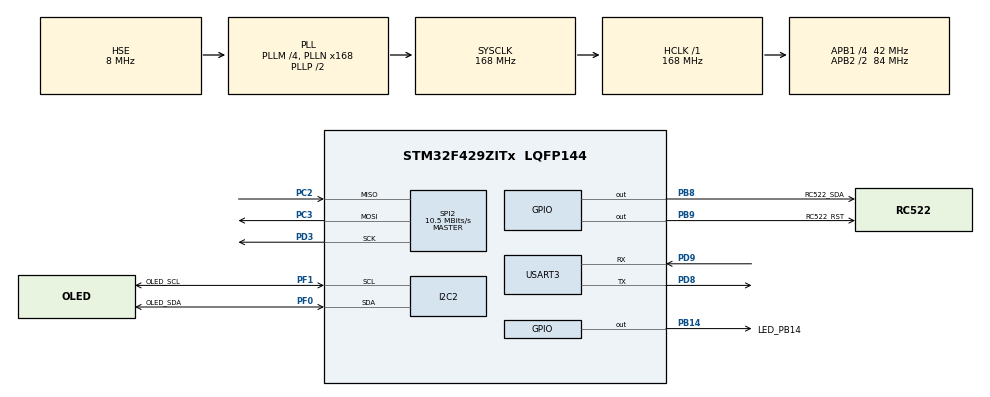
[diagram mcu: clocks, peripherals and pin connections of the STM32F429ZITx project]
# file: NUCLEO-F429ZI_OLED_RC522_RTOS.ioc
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FREERTOS.Tasks01=defaultTask,24,128,StartDefaultTask,Default,NULL,Dynamic,NULL,NULL
I2C2.I2C_Mode=I2C_Fast
Mcu.Family=STM32F4
Mcu.Name=STM32F429ZITx
Mcu.Package=LQFP144
NVIC.PriorityGroup=NVIC_PRIORITYGROUP_4
PA13.Mode=Serial_Wire
PA13.Signal=SYS_JTMS-SWDIO
PA14.Mode=Serial_Wire
PA14.Signal=SYS_JTCK-SWCLK
PB14.GPIO_Label=LED_PB14
PB14.Signal=GPIO_Output
PB8.GPIO_Label=RC522_SDA
PB8.GPIO_Speed=GPIO_SPEED_FREQ_HIGH
PB8.Signal=GPIO_Output
PB9.GPIO_Label=RC522_RST
PB9.GPIO_Speed=GPIO_SPEED_FREQ_HIGH
PB9.Signal=GPIO_Output
PC2.Mode=Full_Duplex_Master
PC2.Signal=SPI2_MISO
PC3.Mode=Full_Duplex_Master
PC3.Signal=SPI2_MOSI
PD3.Mode=Full_Duplex_Master
PD3.Signal=SPI2_SCK
PD8.Mode=Asynchronous
PD8.Signal=USART3_TX
PD9.Mode=Asynchronous
PD9.Signal=USART3_RX
PF0.GPIO_Label=OLED_SDA
PF0.Mode=I2C
PF0.Signal=I2C2_SDA
PF1.GPIO_Label=OLED_SCL
PF1.Mode=I2C
PF1.Signal=I2C2_SCL
PH0/OSC_IN.Mode=HSE-External-Oscillator
PH0/OSC_IN.Signal=RCC_OSC_IN
PH1/OSC_OUT.Mode=HSE-External-Oscillator
PH1/OSC_OUT.Signal=RCC_OSC_OUT
ProjectManager.HeapSize=0x200
ProjectManager.StackSize=0x400
ProjectManager.TargetToolchain=MDK-ARM V5.32
RCC.48MHZClocksFreq_Value=48000000
RCC.AHBFreq_Value=168000000
RCC.APB1CLKDivider=RCC_HCLK_DIV4
RCC.APB1Freq_Value=42000000
RCC.APB1TimFreq_Value=84000000
RCC.APB2CLKDivider=RCC_HCLK_DIV2
RCC.APB2Freq_Value=84000000
RCC.APB2TimCLKDivider=2
RCC.APB2TimFreq_Value=168000000
RCC.CortexFreq_Value=168000000
RCC.HCLKFreq_Value=168000000
RCC.HSE_VALUE=8000000
RCC.HSI_VALUE=16000000
RCC.LSE_VALUE=32768
RCC.PLLM=4
RCC.PLLMUL=RCC_PLL_MUL9
RCC.PLLN=168
RCC.PLLQ=7
RCC.PLLSourceVirtual=RCC_PLLSOURCE_HSE
RCC.PRESCALERUSB=RCC_USBCLKSOURCE_PLL_DIV1_5
RCC.SYSCLKFreq_VALUE=168000000
RCC.SYSCLKSource=RCC_SYSCLKSOURCE_PLLCLK
RCC.SYSCLKSourceVirtual=RCC_SYSCLKSOURCE_PLLCLK
RCC.USBFreq_Value=48000000
RCC.VCOOutputFreq_Value=336000000
SPI2.BaudRatePrescaler=SPI_BAUDRATEPRESCALER_4
SPI2.CalculateBaudRate=10.5 MBits/s
SPI2.Direction=SPI_DIRECTION_2LINES
SPI2.Mode=SPI_MODE_MASTER
SPI2.VirtualType=VM_MASTER
USART3.VirtualMode=VM_ASYNC
VP_FREERTOS_VS_CMSIS_V2.Mode=CMSIS_V2
board=NUCLEO-F429ZI

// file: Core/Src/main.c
/* USER CODE BEGIN Header */
/**
  ******************************************************************************
  * @file           : main.c
  * @brief          : Main program body
  ******************************************************************************
  * @attention
  *
  * Copyright (c) 2025 STMicroelectronics.
  * All rights reserved.
  *
  * This software is licensed under terms that can be found in the LICENSE file
  * in the root directory of this software component.
  * If no LICENSE file comes with this software, it is provided AS-IS.
  *
  ******************************************************************************
  */
/* USER CODE END Header */
#include "main.h"
#include "cmsis_os.h"
#include "i2c.h"
#include "spi.h"
#include "usart.h"
#include "gpio.h"

/* USER CODE BEGIN Includes */
#include "rc522.h"
#include "oled_driver.h"
#include "oled_rtos_task.h"
#include "rc522_rtos_task.h"
/* USER CODE END Includes */

void SystemClock_Config(void);
void MX_FREERTOS_Init(void);

int main(void)
{

  /* MCU Configuration--------------------------------------------------------*/

  /* Reset of all peripherals, Initializes the Flash interface and the Systick. */
  HAL_Init();

  /* Configure the system clock */
  SystemClock_Config();

  /* Initialize all configured peripherals */
  MX_GPIO_Init();
  MX_SPI2_Init();
  MX_USART3_UART_Init();
  MX_I2C2_Init();

  /* Init scheduler */
  osKernelInitialize();

  /* Call init function for freertos objects (in cmsis_os2.c) */
  //MX_FREERTOS_Init();
  OLED_Task_Init();
  RC522_Task_Init();

  /* Start scheduler */
  osKernelStart();

  /* We should never get here as control is now taken by the scheduler */

  /* Infinite loop */
  while (1)
  {

  }
}

void SystemClock_Config(void)
{
  RCC_OscInitTypeDef RCC_OscInitStruct = {0};
  RCC_ClkInitTypeDef RCC_ClkInitStruct = {0};

  /** Configure the main internal regulator output voltage
  */
  __HAL_RCC_PWR_CLK_ENABLE();
  __HAL_PWR_VOLTAGESCALING_CONFIG(PWR_REGULATOR_VOLTAGE_SCALE1);

  /** Initializes the RCC Oscillators according to the specified parameters
  * in the RCC_OscInitTypeDef structure.
  */
  RCC_OscInitStruct.OscillatorType = RCC_OSCILLATORTYPE_HSE;
  RCC_OscInitStruct.HSEState = RCC_HSE_ON;
  RCC_OscInitStruct.PLL.PLLState = RCC_PLL_ON;
  RCC_OscInitStruct.PLL.PLLSource = RCC_PLLSOURCE_HSE;
  RCC_OscInitStruct.PLL.PLLM = 4;
  RCC_OscInitStruct.PLL.PLLN = 168;
  RCC_OscInitStruct.PLL.PLLP = RCC_PLLP_DIV2;
  RCC_OscInitStruct.PLL.PLLQ = 7;
  if (HAL_RCC_OscConfig(&RCC_OscInitStruct) != HAL_OK)
  {
    Error_Handler();
  }

  /** Initializes the CPU, AHB and APB buses clocks
  */
  RCC_ClkInitStruct.ClockType = RCC_CLOCKTYPE_HCLK|RCC_CLOCKTYPE_SYSCLK
                              |RCC_CLOCKTYPE_PCLK1|RCC_CLOCKTYPE_PCLK2;
  RCC_ClkInitStruct.SYSCLKSource = RCC_SYSCLKSOURCE_PLLCLK;
  RCC_ClkInitStruct.AHBCLKDivider = RCC_SYSCLK_DIV1;
  RCC_ClkInitStruct.APB1CLKDivider = RCC_HCLK_DIV4;
  RCC_ClkInitStruct.APB2CLKDivider = RCC_HCLK_DIV2;

  if (HAL_RCC_ClockConfig(&RCC_ClkInitStruct, FLASH_LATENCY_5) != HAL_OK)
  {
    Error_Handler();
  }
}

void Error_Handler(void)
{
  __disable_irq();
  while (1)
  {
  }
}
